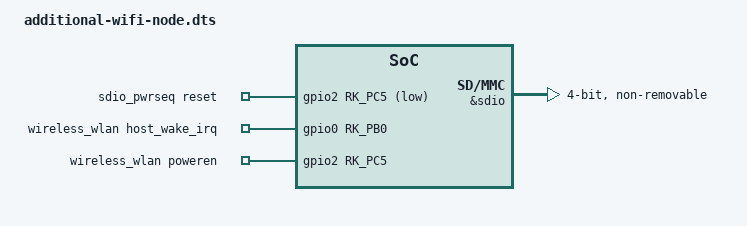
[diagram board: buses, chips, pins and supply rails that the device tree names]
&pinctrl {
	sdio-pwrseq {
		wifi_enable_h: wifi-enable-h {
			rockchip,pins = <2 RK_PC5 RK_FUNC_GPIO &pcfg_pull_none>;
		};
	};
	
	wireless-wlan {
		wifi_host_wake_irq: wifi-host-wake-irq {
			rockchip,pins = <0 RK_PB0 RK_FUNC_GPIO &pcfg_pull_down>;
		};
	};
};

sdio_pwrseq: sdio-pwrseq {
	compatible = "mmc-pwrseq-simple";
	clocks = <&hym8563>;
	clock-names = "ext_clock";
	pinctrl-names = "default";
	pinctrl-0 = <&wifi_enable_h>;
	/*
	* On the module itself this is one of these (depending
	* on the actual card populated):
	* - SDIO_RESET_L_WL_REG_ON
	* - PDN (power down when low)
	*/
	post-power-on-delay-ms = <200>;
	reset-gpios = <&gpio2 RK_PC5 GPIO_ACTIVE_LOW>;
};

wireless_wlan: wireless-wlan {
	compatible = "wlan-platdata";
	wifi_chip_type = "ap6611";
	pinctrl-names = "default";
	pinctrl-0 = <&wifi_host_wake_irq>;
	WIFI,host_wake_irq = <&gpio0 RK_PB0 GPIO_ACTIVE_HIGH>;
	WIFI,poweren_gpio = <&gpio2 RK_PC5 GPIO_ACTIVE_HIGH>;
	status = "okay";
};

/* from mainline linux source: linux/arch/arm64/boot/dts/rockchip/rk3588-base.dtsi*/
/*
sdio: mmc@fe2d0000 {
	compatible = "rockchip,rk3588-dw-mshc", "rockchip,rk3288-dw-mshc";
	reg = <0x00 0xfe2d0000 0x00 0x4000>;
	interrupts = <GIC_SPI 204 IRQ_TYPE_LEVEL_HIGH 0>;
	clocks = <&cru HCLK_SDIO>, <&cru CCLK_SRC_SDIO>,
	<&cru SCLK_SDIO_DRV>, <&cru SCLK_SDIO_SAMPLE>;
	clock-names = "biu", "ciu", "ciu-drive", "ciu-sample";
	fifo-depth = <0x100>;
	max-frequency = <200000000>;
	pinctrl-names = "default";
	pinctrl-0 = <&sdiom1_pins>;
	power-domains = <&power RK3588_PD_SDIO>;
	status = "disabled";
};
*/

&sdio {
	max-frequency = <150000000>;
	no-sd;
	no-mmc;
	bus-width = <4>;
	disable-wp;
	cap-sd-highspeed;
	cap-sdio-irq;
	keep-power-in-suspend;
	mmc-pwrseq = <&sdio_pwrseq>;
	non-removable;
	pinctrl-names = "default";
	pinctrl-0 = <&sdiom0_pins>;
	sd-uhs-sdr104;
	status = "okay";
};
